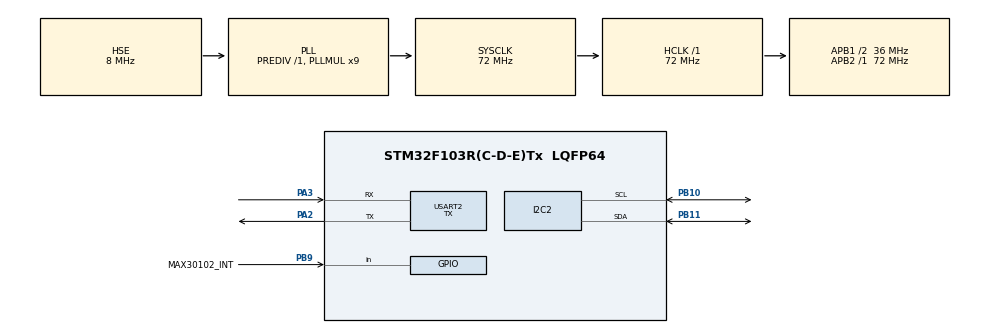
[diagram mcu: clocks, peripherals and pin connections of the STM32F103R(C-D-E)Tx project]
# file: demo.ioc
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I2C2.I2C_Mode=I2C_Standard
I2C2.NoStretchMode=I2C_NOSTRETCH_DISABLE
Mcu.Family=STM32F1
Mcu.Name=STM32F103R(C-D-E)Tx
Mcu.Package=LQFP64
NVIC.PriorityGroup=NVIC_PRIORITYGROUP_4
PA13.Mode=Serial_Wire
PA13.Signal=SYS_JTMS-SWDIO
PA14.Mode=Serial_Wire
PA14.Signal=SYS_JTCK-SWCLK
PA2.Mode=Asynchronous
PA2.Signal=USART2_TX
PA3.Mode=Asynchronous
PA3.Signal=USART2_RX
PB10.Mode=I2C
PB10.Signal=I2C2_SCL
PB11.Mode=I2C
PB11.Signal=I2C2_SDA
PB9.GPIO_Label=MAX30102_INT
PB9.Signal=GPIO_Input
PD0-OSC_IN.Mode=HSE-External-Oscillator
PD0-OSC_IN.Signal=RCC_OSC_IN
PD1-OSC_OUT.Mode=HSE-External-Oscillator
PD1-OSC_OUT.Signal=RCC_OSC_OUT
ProjectManager.HeapSize=0x200
ProjectManager.StackSize=0x400
ProjectManager.TargetToolchain=MDK-ARM V5
RCC.AHBFreq_Value=72000000
RCC.APB1CLKDivider=RCC_HCLK_DIV2
RCC.APB1Freq_Value=36000000
RCC.APB1TimFreq_Value=72000000
RCC.APB2Freq_Value=72000000
RCC.APB2TimFreq_Value=72000000
RCC.HCLKFreq_Value=72000000
RCC.PLLMUL=RCC_PLL_MUL9
RCC.PLLSourceVirtual=RCC_PLLSOURCE_HSE
RCC.SYSCLKFreq_VALUE=72000000
RCC.SYSCLKSource=RCC_SYSCLKSOURCE_PLLCLK
RCC.USBFreq_Value=72000000
USART2.Mode=MODE_TX
USART2.VirtualMode=VM_ASYNC
board=custom

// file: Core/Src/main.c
/* USER CODE BEGIN Header */
/**
 ******************************************************************************
 * @file           : main.c
 * @brief          : Main program body
 ******************************************************************************
 * @attention
 *
 * <h2><center>&copy; Copyright (c) 2022 STMicroelectronics.
 * All rights reserved.</center></h2>
 *
 * This software component is licensed by ST under BSD 3-Clause license,
 * the "License"; You may not use this file except in compliance with the
 * License. You may obtain a copy of the License at:
 *                        opensource.org/licenses/BSD-3-Clause
 *
 ******************************************************************************
 */
/* USER CODE END Header */

#include "main.h"
#include "gpio.h"
#include "i2c.h"
#include "usart.h"

/* USER CODE BEGIN Includes */
#include "MAX30102/blood.h"
#include "MAX30102/max30102.h"

/* USER CODE END Includes */

void SystemClock_Config(void);

int main(void) {

    /* MCU Configuration--------------------------------------------------------*/

    /* Reset of all peripherals, Initializes the Flash interface and the Systick. */
    HAL_Init();

    /* Configure the system clock */
    SystemClock_Config();

    /* Initialize all configured peripherals */
    MX_GPIO_Init();
    MX_I2C2_Init();
    MX_USART2_UART_Init();

    /* Infinite loop */
    /* USER CODE BEGIN WHILE */

    // MAX30102_WriteReg(REG_INTR_ENABLE_1, 0xc0);  // INTR setting
    // MAX30102_WriteReg(REG_INTR_ENABLE_2, 0x00);  //
    // MAX30102_WriteReg(REG_FIFO_WR_PTR, 0x00);    // FIFO_WR_PTR[4:0]
    // MAX30102_WriteReg(REG_OVF_COUNTER, 0x00);    // OVF_COUNTER[4:0]
    // MAX30102_WriteReg(REG_FIFO_RD_PTR, 0x00);    // FIFO_RD_PTR[4:0]

    // MAX30102_WriteReg(REG_FIFO_CONFIG, 0x0f);  // sample avg = 1, fifo rollover=false, fifo almost full = 17
    // MAX30102_WriteReg(REG_MODE_CONFIG, 0x03);  // 0x02 for Red only, 0x03 for SpO2 mode 0x07 multimode LED
    // MAX30102_WriteReg(REG_SPO2_CONFIG, 0x27);  // SPO2_ADC range = 4096nA, SPO2 sample rate (50 Hz), LED pulseWidth (400uS)
    // MAX30102_WriteReg(REG_LED1_PA, 0x32);      // Choose value for ~ 10mA for LED1
    // MAX30102_WriteReg(REG_LED2_PA, 0x32);      // Choose value for ~ 10mA for LED2
    // MAX30102_WriteReg(REG_PILOT_PA, 0x7f);     // Choose value for ~ 25mA for Pilot LED

    // activeLEDs = 2;

    MAX30102_Init(0x7f, SAMPLE_AVERAGE_1, LED_MODE_REDIRONLY, SAMPLE_RATE_50, PULSE_WIDTH_411, ADC_RANGE_4096);

    MAX30102_SetRedCurrent(0x32);
    MAX30102_SetIRCurrent(0x32);

    max30102_fifo_t fifo;
    for (uint8_t i = 0; i < 128; i++) {
        while (MAX30102_CheckFIFO() != HAL_OK) {}
        MAX30102_ReadFIFO2(&fifo);
    }

    while (1) {
        blood_Loop();
        /* USER CODE END WHILE */

    }
}

void SystemClock_Config(void) {
    RCC_OscInitTypeDef RCC_OscInitStruct = {0};
    RCC_ClkInitTypeDef RCC_ClkInitStruct = {0};

    /** Initializes the CPU, AHB and APB busses clocks
     */
    RCC_OscInitStruct.OscillatorType = RCC_OSCILLATORTYPE_HSE;
    RCC_OscInitStruct.HSEState       = RCC_HSE_ON;
    RCC_OscInitStruct.HSEPredivValue = RCC_HSE_PREDIV_DIV1;
    RCC_OscInitStruct.HSIState       = RCC_HSI_ON;
    RCC_OscInitStruct.PLL.PLLState   = RCC_PLL_ON;
    RCC_OscInitStruct.PLL.PLLSource  = RCC_PLLSOURCE_HSE;
    RCC_OscInitStruct.PLL.PLLMUL     = RCC_PLL_MUL9;
    if (HAL_RCC_OscConfig(&RCC_OscInitStruct) != HAL_OK) {
        Error_Handler();
    }
    /** Initializes the CPU, AHB and APB busses clocks
     */
    RCC_ClkInitStruct.ClockType      = RCC_CLOCKTYPE_HCLK | RCC_CLOCKTYPE_SYSCLK | RCC_CLOCKTYPE_PCLK1 | RCC_CLOCKTYPE_PCLK2;
    RCC_ClkInitStruct.SYSCLKSource   = RCC_SYSCLKSOURCE_PLLCLK;
    RCC_ClkInitStruct.AHBCLKDivider  = RCC_SYSCLK_DIV1;
    RCC_ClkInitStruct.APB1CLKDivider = RCC_HCLK_DIV2;
    RCC_ClkInitStruct.APB2CLKDivider = RCC_HCLK_DIV1;

    if (HAL_RCC_ClockConfig(&RCC_ClkInitStruct, FLASH_LATENCY_2) != HAL_OK) {
        Error_Handler();
    }
}

void Error_Handler(void) {
}

/************************ (C) COPYRIGHT STMicroelectronics *****END OF FILE****/
